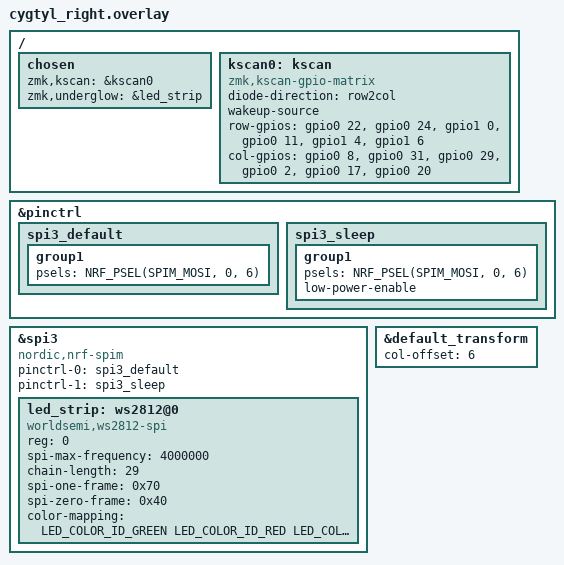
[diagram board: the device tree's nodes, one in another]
/*
 * Copyright (c) 2025 Noir Guo
 *
 * SPDX-License-Identifier: MIT
 */

#include "cygtyl.dtsi"

&pinctrl {
// Other pinctrl definitions for other hardware

    spi3_default: spi3_default {
        group1 {
            psels = <NRF_PSEL(SPIM_MOSI, 0, 6)>;
        };
    };

    spi3_sleep: spi3_sleep {
        group1 {
            psels = <NRF_PSEL(SPIM_MOSI, 0, 6)>;
            low-power-enable;
        };
    };
};

&spi3 {
    compatible = "nordic,nrf-spim";
    status = "okay";

    pinctrl-0 = <&spi3_default>;
    pinctrl-1 = <&spi3_sleep>;
    pinctrl-names = "default", "sleep";

    led_strip: ws2812@0 {
        compatible = "worldsemi,ws2812-spi";

        /* SPI */
        reg = <0>; /* ignored, but necessary for SPI bindings */
        spi-max-frequency = <4000000>;

        /* WS2812 */
        chain-length = <29>; /* arbitrary; change at will */
        spi-one-frame = <0x70>;
        spi-zero-frame = <0x40>;

        color-mapping = <
            LED_COLOR_ID_GREEN
            LED_COLOR_ID_RED
            LED_COLOR_ID_BLUE
        >;
    };
};

&default_transform {
    col-offset = <6>;
};

/ {
    chosen {
        zmk,kscan = &kscan0;
        zmk,underglow = &led_strip;
    };
    
    kscan0: kscan {
        compatible = "zmk,kscan-gpio-matrix";
        diode-direction = "row2col";
        wakeup-source;

        row-gpios
            = <&gpio0 22 GPIO_ACTIVE_HIGH>
            , <&gpio0 24 GPIO_ACTIVE_HIGH>
            , <&gpio1 0  GPIO_ACTIVE_HIGH>
            , <&gpio0 11 GPIO_ACTIVE_HIGH>
            , <&gpio1 4  GPIO_ACTIVE_HIGH>
            , <&gpio1 6  GPIO_ACTIVE_HIGH>
            ;

        col-gpios
            = <&gpio0 8  (GPIO_ACTIVE_HIGH | GPIO_PULL_DOWN)>
            , <&gpio0 31 (GPIO_ACTIVE_HIGH | GPIO_PULL_DOWN)>
            , <&gpio0 29 (GPIO_ACTIVE_HIGH | GPIO_PULL_DOWN)>
            , <&gpio0 2  (GPIO_ACTIVE_HIGH | GPIO_PULL_DOWN)>
            , <&gpio0 17 (GPIO_ACTIVE_HIGH | GPIO_PULL_DOWN)>
            , <&gpio0 20 (GPIO_ACTIVE_HIGH | GPIO_PULL_DOWN)>
            ;
    };
};


